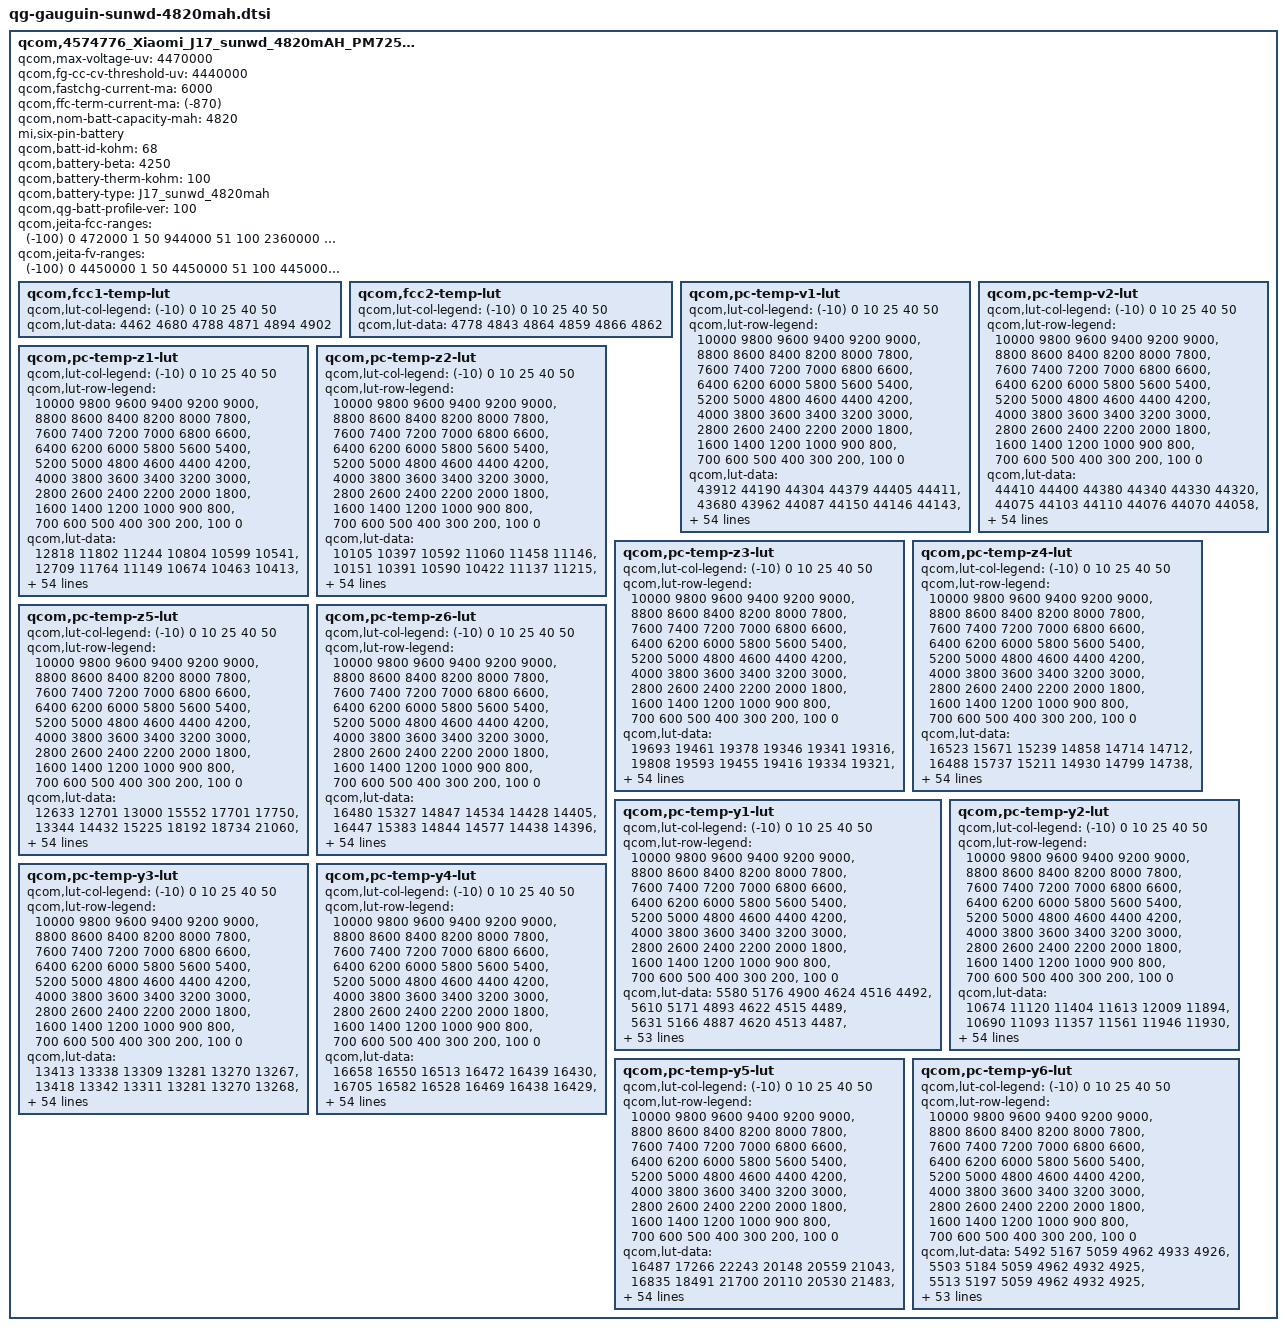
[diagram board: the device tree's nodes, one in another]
qcom,4574776_Xiaomi_J17_sunwd_4820mAH_PM7250B {
    /* 4574776_Xiaomi_J17_sunwd_4820mAH_PM7250B_averaged_MasterSlave_May19th2020 */
    qcom,max-voltage-uv = <4470000>;
    qcom,fg-cc-cv-threshold-uv = <4440000>;
    qcom,fastchg-current-ma = <6000>;
    qcom,ffc-term-current-ma = <(-870)>;
    qcom,nom-batt-capacity-mah = <4820>;
    mi,six-pin-battery;
    qcom,batt-id-kohm = <68>;
    qcom,battery-beta = <4250>;
    qcom,battery-therm-kohm = <100>;
    qcom,battery-type = "J17_sunwd_4820mah";
    qcom,qg-batt-profile-ver = <100>;
   	qcom,jeita-fcc-ranges = <(-100)	0	472000
			1  50  944000
			51  100	2360000
			101 150	3776000
			151 480	6000000
			481 600	2360000>;
	qcom,jeita-fv-ranges = <(-100)  0   4450000
			1   50  4450000
			51  100	4450000
			101 150	4450000
			151 480	4480000
			481 600	4200000>;

	qcom,fcc1-temp-lut {
		qcom,lut-col-legend = <(-10) 0 10 25 40 50>;
		qcom,lut-data = <4462 4680 4788 4871 4894 4902>;
	};

	qcom,fcc2-temp-lut {
		qcom,lut-col-legend = <(-10) 0 10 25 40 50>;
		qcom,lut-data = <4778 4843 4864 4859 4866 4862>;
	};

	qcom,pc-temp-v1-lut {
		qcom,lut-col-legend = <(-10) 0 10 25 40 50>;
		qcom,lut-row-legend = <10000 9800 9600 9400 9200 9000>,
			<8800 8600 8400 8200 8000 7800>,
			<7600 7400 7200 7000 6800 6600>,
			<6400 6200 6000 5800 5600 5400>,
			<5200 5000 4800 4600 4400 4200>,
			<4000 3800 3600 3400 3200 3000>,
			<2800 2600 2400 2200 2000 1800>,
			<1600 1400 1200 1000 900 800>,
			<700 600 500 400 300 200>,
			<100 0>;
		qcom,lut-data = <43912 44190 44304 44379 44405 44411>,
			<43680 43962 44087 44150 44146 44143>,
			<43449 43743 43869 43937 43929 43924>,
			<43218 43528 43654 43725 43720 43719>,
			<42987 43304 43439 43507 43504 43505>,
			<42751 43068 43214 43284 43285 43290>,
			<42514 42827 42973 43049 43058 43065>,
			<42281 42588 42727 42803 42819 42826>,
			<42053 42347 42481 42555 42575 42581>,
			<41829 42109 42234 42308 42328 42336>,
			<41611 41876 41992 42062 42079 42089>,
			<41396 41647 41755 41820 41836 41847>,
			<41189 41424 41524 41579 41595 41609>,
			<40996 41207 41298 41345 41360 41375>,
			<40810 40994 41077 41120 41132 41146>,
			<40622 40785 40864 40902 40911 40922>,
			<40420 40582 40657 40692 40698 40706>,
			<40220 40387 40458 40488 40491 40498>,
			<40044 40198 40276 40295 40295 40300>,
			<39891 40018 40107 40122 40116 40118>,
			<39744 39854 39922 39946 39943 39943>,
			<39587 39698 39695 39722 39735 39740>,
			<39428 39504 39462 39454 39487 39501>,
			<39268 39215 39249 39232 39262 39278>,
			<39096 38953 39046 39065 39076 39089>,
			<38928 38824 38889 38922 38913 38921>,
			<38808 38739 38781 38793 38779 38781>,
			<38723 38666 38690 38677 38667 38664>,
			<38654 38597 38597 38575 38564 38557>,
			<38593 38535 38505 38482 38466 38457>,
			<38541 38474 38423 38400 38376 38366>,
			<38493 38413 38350 38326 38294 38281>,
			<38446 38358 38285 38260 38220 38203>,
			<38400 38306 38230 38202 38155 38132>,
			<38358 38259 38183 38153 38099 38071>,
			<38320 38219 38141 38106 38046 38011>,
			<38281 38186 38106 38058 37987 37941>,
			<38237 38148 38070 38009 37926 37862>,
			<38188 38086 38014 37944 37853 37780>,
			<38130 38001 37924 37857 37767 37695>,
			<38053 37902 37820 37754 37668 37600>,
			<37951 37783 37702 37638 37555 37482>,
			<37817 37642 37563 37502 37422 37343>,
			<37646 37468 37395 37335 37256 37181>,
			<37458 37305 37230 37176 37106 37037>,
			<37313 37189 37129 37073 37017 36953>,
			<37259 37157 37094 37047 36993 36932>,
			<37213 37128 37071 37030 36976 36920>,
			<37176 37111 37056 37011 36959 36903>,
			<37144 37070 37016 36968 36911 36839>,
			<37102 36934 36807 36716 36624 36537>,
			<36971 36511 36353 36266 36178 36082>,
			<36571 35941 35752 35670 35583 35487>,
			<36008 35149 34896 34852 34771 34672>,
			<35112 33752 33465 33560 33492 33393>,
			<30000 30000 30000 30000 30000 30000>;
	};

	qcom,pc-temp-v2-lut {
		qcom,lut-col-legend = <(-10) 0 10 25 40 50>;
		qcom,lut-row-legend = <10000 9800 9600 9400 9200 9000>,
			<8800 8600 8400 8200 8000 7800>,
			<7600 7400 7200 7000 6800 6600>,
			<6400 6200 6000 5800 5600 5400>,
			<5200 5000 4800 4600 4400 4200>,
			<4000 3800 3600 3400 3200 3000>,
			<2800 2600 2400 2200 2000 1800>,
			<1600 1400 1200 1000 900 800>,
			<700 600 500 400 300 200>,
			<100 0>;
		qcom,lut-data = <44410 44400 44380 44340 44330 44320>,
			<44075 44103 44110 44076 44070 44058>,
			<43773 43831 43856 43825 43823 43809>,
			<43511 43591 43623 43593 43592 43578>,
			<43288 43381 43411 43379 43378 43364>,
			<43067 43165 43194 43159 43159 43145>,
			<42834 42925 42957 42922 42924 42911>,
			<42596 42677 42712 42679 42683 42671>,
			<42357 42429 42467 42434 42440 42429>,
			<42113 42181 42219 42187 42193 42183>,
			<41876 41936 41973 41942 41949 41940>,
			<41660 41697 41731 41700 41708 41700>,
			<41451 41464 41493 41462 41470 41463>,
			<41230 41240 41260 41231 41238 41232>,
			<40996 41024 41032 41005 41011 41005>,
			<40747 40811 40810 40786 40791 40786>,
			<40471 40603 40599 40573 40579 40574>,
			<40179 40391 40392 40366 40375 40369>,
			<39919 40146 40187 40174 40184 40177>,
			<39690 39866 39984 39994 40002 39997>,
			<39477 39604 39764 39792 39804 39801>,
			<39272 39372 39501 39541 39572 39570>,
			<39079 39160 39243 39286 39336 39335>,
			<38899 38976 39037 39076 39123 39126>,
			<38733 38812 38861 38889 38922 38930>,
			<38575 38663 38708 38733 38759 38769>,
			<38418 38527 38575 38603 38632 38642>,
			<38267 38403 38457 38490 38521 38531>,
			<38157 38286 38347 38384 38415 38425>,
			<38081 38177 38245 38285 38317 38326>,
			<38019 38080 38153 38196 38228 38236>,
			<37960 37991 38067 38114 38149 38154>,
			<37908 37916 37989 38039 38075 38078>,
			<37855 37865 37915 37970 38007 38008>,
			<37801 37829 37845 37907 37944 37941>,
			<37746 37792 37790 37839 37864 37855>,
			<37689 37757 37750 37768 37759 37730>,
			<37632 37719 37709 37691 37649 37600>,
			<37565 37669 37651 37607 37553 37499>,
			<37486 37604 37578 37518 37461 37407>,
			<37396 37522 37487 37422 37365 37310>,
			<37293 37405 37361 37319 37265 37209>,
			<37176 37257 37224 37201 37149 37092>,
			<37067 37059 37073 37064 37015 36955>,
			<36960 36885 36907 36913 36872 36822>,
			<36857 36793 36841 36873 36846 36798>,
			<36812 36759 36811 36854 36834 36785>,
			<36767 36725 36783 36839 36817 36767>,
			<36716 36684 36738 36804 36788 36736>,
			<36670 36618 36646 36720 36690 36606>,
			<36596 36423 36355 36426 36347 36247>,
			<36448 35985 35818 35930 35841 35726>,
			<36075 35308 35101 35268 35174 35049>,
			<35423 34244 34089 34369 34243 34096>,
			<34457 32755 32350 32876 32827 32696>,
			<32941 29856 27432 27497 27882 27883>;
	};

	qcom,pc-temp-z1-lut {
		qcom,lut-col-legend = <(-10) 0 10 25 40 50>;
		qcom,lut-row-legend = <10000 9800 9600 9400 9200 9000>,
			<8800 8600 8400 8200 8000 7800>,
			<7600 7400 7200 7000 6800 6600>,
			<6400 6200 6000 5800 5600 5400>,
			<5200 5000 4800 4600 4400 4200>,
			<4000 3800 3600 3400 3200 3000>,
			<2800 2600 2400 2200 2000 1800>,
			<1600 1400 1200 1000 900 800>,
			<700 600 500 400 300 200>,
			<100 0>;
		qcom,lut-data = <12818 11802 11244 10804 10599 10541>,
			<12709 11764 11149 10674 10463 10413>,
			<12658 11708 11083 10635 10438 10392>,
			<12627 11642 11052 10612 10425 10381>,
			<12613 11597 11033 10593 10416 10375>,
			<12613 11570 11014 10580 10410 10372>,
			<12613 11547 10992 10571 10407 10370>,
			<12613 11522 10973 10565 10405 10369>,
			<12611 11496 10957 10560 10404 10368>,
			<12608 11480 10944 10556 10402 10367>,
			<12601 11473 10940 10552 10400 10367>,
			<12586 11468 10940 10549 10399 10367>,
			<12575 11460 10941 10547 10398 10367>,
			<12583 11447 10940 10545 10397 10367>,
			<12605 11439 10938 10545 10397 10367>,
			<12615 11437 10935 10545 10398 10368>,
			<12606 11436 10931 10545 10398 10368>,
			<12592 11435 10928 10546 10398 10368>,
			<12592 11435 10929 10547 10399 10369>,
			<12616 11435 10933 10549 10400 10370>,
			<12639 11437 10936 10551 10401 10371>,
			<12638 11443 10938 10553 10402 10372>,
			<12629 11449 10939 10555 10404 10374>,
			<12624 11455 10942 10558 10406 10376>,
			<12639 11459 10949 10562 10408 10378>,
			<12667 11458 10953 10566 10411 10379>,
			<12687 11454 10954 10569 10413 10381>,
			<12704 11452 10954 10573 10415 10382>,
			<12714 11456 10959 10577 10416 10383>,
			<12709 11463 10971 10579 10419 10385>,
			<12683 11469 10978 10582 10421 10387>,
			<12665 11473 10975 10585 10423 10389>,
			<12666 11477 10972 10588 10425 10391>,
			<12668 11480 10973 10592 10427 10393>,
			<12672 11483 10980 10597 10429 10394>,
			<12689 11488 10989 10602 10432 10395>,
			<12708 11496 10997 10606 10434 10397>,
			<12711 11507 11004 10611 10437 10399>,
			<12706 11517 11009 10615 10440 10400>,
			<12702 11529 11013 10620 10442 10401>,
			<12721 11544 11017 10625 10444 10402>,
			<12759 11568 11027 10630 10445 10404>,
			<12762 11587 11041 10635 10446 10405>,
			<12758 11601 11062 10639 10448 10406>,
			<12780 11598 11067 10646 10452 10407>,
			<12782 11640 11062 10649 10453 10408>,
			<12723 11631 11064 10657 10456 10408>,
			<12718 11631 11078 10653 10452 10408>,
			<12746 11617 11067 10654 10453 10409>,
			<12768 11608 11086 10660 10456 10410>,
			<12774 11668 11086 10663 10460 10412>,
			<12794 11655 11112 10672 10464 10416>,
			<12837 11706 11121 10684 10469 10421>,
			<12934 11736 11137 10696 10477 10427>,
			<12934 11736 11137 10696 10477 10427>,
			<12934 11736 11137 10696 10477 10427>;
	};

	qcom,pc-temp-z2-lut {
		qcom,lut-col-legend = <(-10) 0 10 25 40 50>;
		qcom,lut-row-legend = <10000 9800 9600 9400 9200 9000>,
			<8800 8600 8400 8200 8000 7800>,
			<7600 7400 7200 7000 6800 6600>,
			<6400 6200 6000 5800 5600 5400>,
			<5200 5000 4800 4600 4400 4200>,
			<4000 3800 3600 3400 3200 3000>,
			<2800 2600 2400 2200 2000 1800>,
			<1600 1400 1200 1000 900 800>,
			<700 600 500 400 300 200>,
			<100 0>;
		qcom,lut-data = <10105 10397 10592 11060 11458 11146>,
			<10151 10391 10590 10422 11137 11215>,
			<10173 10380 10586 10676 11129 11202>,
			<10186 10361 10567 10857 11113 11175>,
			<10191 10339 10524 10822 11082 11124>,
			<10191 10304 10485 10762 11027 11035>,
			<10191 10271 10446 10746 10982 11000>,
			<10191 10253 10420 10744 10944 11013>,
			<10198 10240 10426 10743 10922 11035>,
			<10208 10236 10448 10751 10935 11071>,
			<10216 10238 10469 10768 10966 11121>,
			<10224 10245 10490 10781 10975 11135>,
			<10233 10260 10509 10793 10975 11111>,
			<10243 10299 10525 10805 10975 11090>,
			<10255 10334 10539 10816 10981 11109>,
			<10261 10352 10553 10826 10996 11158>,
			<10261 10366 10566 10831 11016 11195>,
			<10262 10387 10580 10834 11049 11222>,
			<10263 10419 10594 10839 11072 11244>,
			<10272 10439 10607 10853 11078 11261>,
			<10281 10440 10624 10872 11082 11276>,
			<10279 10439 10659 10888 11094 11294>,
			<10272 10439 10689 10903 11123 11316>,
			<10262 10449 10677 10921 11139 11326>,
			<10248 10464 10627 10953 11132 11208>,
			<10232 10478 10604 10978 11113 11026>,
			<10229 10491 10615 10952 11060 10983>,
			<10242 10501 10630 10869 10929 10971>,
			<10257 10508 10634 10829 10868 10968>,
			<10262 10513 10635 10820 10879 10996>,
			<10263 10516 10637 10816 10901 11046>,
			<10265 10518 10642 10830 10928 11090>,
			<10269 10520 10650 10872 10965 11134>,
			<10275 10526 10665 10906 11010 11187>,
			<10284 10534 10690 10928 11064 11260>,
			<10300 10539 10708 10950 11129 11337>,
			<10320 10541 10714 10983 11214 11402>,
			<10338 10544 10719 11022 11316 11461>,
			<10355 10553 10728 11050 11381 11489>,
			<10366 10565 10745 11071 11425 11498>,
			<10356 10569 10753 11081 11448 11506>,
			<10324 10563 10747 11072 11398 11540>,
			<10277 10561 10742 11053 11314 11579>,
			<10200 10577 10745 11030 11302 11453>,
			<10084 10789 10840 11049 11321 11397>,
			<10060 10842 10910 11091 11354 11424>,
			<10032 10873 10922 11085 11336 11438>,
			<9978 10898 10916 11052 11355 11505>,
			<9802 11178 11309 11021 11300 11606>,
			<9716 11193 11279 11090 11451 11561>,
			<9699 11138 11471 11114 11122 11202>,
			<9623 10896 11478 11060 11132 11124>,
			<9518 10630 11477 10988 11056 11074>,
			<9294 10426 10747 10885 10979 11031>,
			<9294 10426 10747 10885 10979 11031>,
			<9294 10426 10747 10885 10979 11031>;
	};

	qcom,pc-temp-z3-lut {
		qcom,lut-col-legend = <(-10) 0 10 25 40 50>;
		qcom,lut-row-legend = <10000 9800 9600 9400 9200 9000>,
			<8800 8600 8400 8200 8000 7800>,
			<7600 7400 7200 7000 6800 6600>,
			<6400 6200 6000 5800 5600 5400>,
			<5200 5000 4800 4600 4400 4200>,
			<4000 3800 3600 3400 3200 3000>,
			<2800 2600 2400 2200 2000 1800>,
			<1600 1400 1200 1000 900 800>,
			<700 600 500 400 300 200>,
			<100 0>;
		qcom,lut-data = <19693 19461 19378 19346 19341 19316>,
			<19808 19593 19455 19416 19334 19321>,
			<19856 19644 19503 19409 19344 19325>,
			<19884 19676 19514 19405 19350 19327>,
			<19896 19690 19519 19407 19353 19327>,
			<19888 19698 19523 19411 19354 19325>,
			<19867 19702 19525 19412 19354 19324>,
			<19850 19700 19527 19408 19345 19322>,
			<19837 19692 19524 19404 19337 19321>,
			<19824 19684 19515 19395 19336 19321>,
			<19811 19678 19506 19386 19335 19321>,
			<19798 19672 19498 19383 19334 19320>,
			<19784 19662 19491 19382 19332 19314>,
			<19768 19643 19486 19380 19330 19309>,
			<19751 19632 19482 19376 19326 19308>,
			<19744 19633 19479 19370 19321 19308>,
			<19751 19635 19475 19366 19319 19308>,
			<19762 19633 19471 19363 19318 19307>,
			<19763 19609 19468 19362 19318 19305>,
			<19750 19590 19465 19363 19317 19304>,
			<19738 19594 19464 19364 19316 19303>,
			<19746 19605 19475 19368 19316 19303>,
			<19774 19614 19488 19376 19318 19306>,
			<19792 19622 19486 19379 19320 19310>,
			<19795 19627 19472 19378 19335 19319>,
			<19796 19624 19465 19375 19352 19328>,
			<19797 19613 19467 19381 19352 19329>,
			<19798 19605 19470 19398 19345 19328>,
			<19798 19603 19476 19404 19339 19326>,
			<19797 19601 19486 19400 19336 19321>,
			<19789 19601 19490 19394 19333 19315>,
			<19780 19602 19488 19389 19331 19311>,
			<19773 19602 19485 19384 19328 19309>,
			<19767 19602 19481 19380 19326 19308>,
			<19761 19600 19476 19375 19324 19307>,
			<19758 19598 19473 19373 19323 19306>,
			<19755 19595 19471 19372 19323 19306>,
			<19750 19591 19469 19372 19323 19305>,
			<19737 19586 19466 19372 19323 19305>,
			<19715 19580 19460 19369 19324 19307>,
			<19560 19574 19455 19366 19325 19309>,
			<19292 19566 19452 19363 19322 19310>,
			<19260 19557 19448 19361 19319 19311>,
			<19260 19546 19442 19358 19320 19310>,
			<19260 19492 19427 19352 19318 19308>,
			<19260 19473 19401 19346 19311 19303>,
			<19261 19455 19405 19345 19310 19301>,
			<19261 19438 19400 19340 19309 19295>,
			<19262 19304 19326 19339 19307 19292>,
			<19263 19300 19337 19337 19303 19296>,
			<19263 19295 19312 19341 19322 19306>,
			<19264 19297 19313 19346 19316 19306>,
			<19266 19297 19303 19350 19320 19309>,
			<19276 19323 19412 19355 19320 19309>,
			<19276 19323 19412 19355 19320 19309>,
			<19276 19323 19412 19355 19320 19309>;
	};

	qcom,pc-temp-z4-lut {
		qcom,lut-col-legend = <(-10) 0 10 25 40 50>;
		qcom,lut-row-legend = <10000 9800 9600 9400 9200 9000>,
			<8800 8600 8400 8200 8000 7800>,
			<7600 7400 7200 7000 6800 6600>,
			<6400 6200 6000 5800 5600 5400>,
			<5200 5000 4800 4600 4400 4200>,
			<4000 3800 3600 3400 3200 3000>,
			<2800 2600 2400 2200 2000 1800>,
			<1600 1400 1200 1000 900 800>,
			<700 600 500 400 300 200>,
			<100 0>;
		qcom,lut-data = <16523 15671 15239 14858 14714 14712>,
			<16488 15737 15211 14930 14799 14738>,
			<16361 15654 15166 14897 14778 14729>,
			<16049 15444 15096 14856 14749 14714>,
			<15778 15282 14998 14818 14725 14700>,
			<15664 15170 14923 14780 14703 14685>,
			<15584 15080 14872 14750 14692 14676>,
			<15515 15013 14832 14725 14689 14671>,
			<15449 14959 14798 14711 14685 14667>,
			<15394 14915 14770 14708 14679 14661>,
			<15356 14877 14755 14706 14672 14655>,
			<15326 14845 14749 14702 14667 14652>,
			<15304 14822 14745 14693 14662 14651>,
			<15288 14805 14740 14688 14659 14651>,
			<15275 14792 14735 14685 14656 14648>,
			<15271 14781 14733 14684 14654 14641>,
			<15290 14772 14733 14682 14652 14636>,
			<15317 14773 14733 14680 14647 14632>,
			<15316 14791 14729 14677 14643 14629>,
			<15255 14806 14717 14672 14640 14626>,
			<15197 14790 14712 14667 14638 14625>,
			<15202 14756 14725 14683 14647 14630>,
			<15240 14750 14750 14737 14691 14663>,
			<15296 14823 14783 14762 14717 14684>,
			<15425 14897 14827 14763 14705 14680>,
			<15589 14901 14846 14763 14688 14671>,
			<15636 14895 14830 14753 14680 14664>,
			<15593 14886 14804 14721 14676 14657>,
			<15529 14872 14782 14705 14672 14652>,
			<15471 14855 14762 14700 14667 14650>,
			<15406 14840 14751 14698 14662 14648>,
			<15358 14827 14749 14698 14659 14645>,
			<15337 14816 14748 14698 14656 14641>,
			<15322 14809 14748 14698 14655 14639>,
			<15307 14803 14748 14698 14656 14638>,
			<15294 14797 14749 14697 14656 14638>,
			<15279 14791 14746 14699 14660 14643>,
			<15254 14785 14743 14704 14670 14657>,
			<15205 14778 14740 14705 14673 14661>,
			<15170 14770 14738 14705 14671 14656>,
			<15258 14760 14734 14704 14668 14649>,
			<15437 14743 14721 14697 14663 14643>,
			<15448 14726 14703 14684 14657 14639>,
			<15411 14708 14689 14676 14653 14638>,
			<15358 14680 14665 14662 14647 14635>,
			<15348 14675 14658 14646 14639 14628>,
			<15335 14685 14647 14639 14632 14623>,
			<15325 14700 14644 14632 14623 14619>,
			<15313 14844 14720 14624 14616 14613>,
			<15298 14843 14703 14625 14621 14612>,
			<15275 14846 14737 14632 14614 14612>,
			<15262 14852 14740 14626 14618 14611>,
			<15287 14856 14751 14622 14615 14609>,
			<15337 14844 14644 14617 14614 14609>,
			<15337 14844 14644 14617 14614 14609>,
			<15337 14844 14644 14617 14614 14609>;
	};

	qcom,pc-temp-z5-lut {
		qcom,lut-col-legend = <(-10) 0 10 25 40 50>;
		qcom,lut-row-legend = <10000 9800 9600 9400 9200 9000>,
			<8800 8600 8400 8200 8000 7800>,
			<7600 7400 7200 7000 6800 6600>,
			<6400 6200 6000 5800 5600 5400>,
			<5200 5000 4800 4600 4400 4200>,
			<4000 3800 3600 3400 3200 3000>,
			<2800 2600 2400 2200 2000 1800>,
			<1600 1400 1200 1000 900 800>,
			<700 600 500 400 300 200>,
			<100 0>;
		qcom,lut-data = <12633 12701 13000 15552 17701 17750>,
			<13344 14432 15225 18192 18734 21060>,
			<13968 15369 16802 18669 20121 21603>,
			<14563 16028 17535 19038 21256 21851>,
			<14969 16708 17987 19627 22206 22089>,
			<15142 17432 18574 20284 23015 22276>,
			<15254 18148 19404 21173 23155 22496>,
			<15387 18825 20362 22489 22010 22756>,
			<15596 19472 21577 23184 20963 23099>,
			<15777 20254 22973 22486 21271 23849>,
			<15815 21374 23477 21448 22099 24985>,
			<15821 22625 23499 21487 22598 25203>,
			<15824 23640 23519 22468 22898 23306>,
			<15764 24449 23698 23029 23045 21599>,
			<15613 25519 24214 22572 22541 21967>,
			<15540 28226 24757 21960 21601 23092>,
			<15612 31481 25413 21935 21499 24131>,
			<15755 31664 25909 22263 22360 25069>,
			<15900 27188 25892 22817 23443 26106>,
			<16047 23531 25714 24764 24698 27672>,
			<16267 25617 25890 27255 25857 29255>,
			<17049 31466 34370 28740 25383 28690>,
			<18776 37463 44197 29896 22202 23571>,
			<19758 44926 42140 30102 20352 20236>,
			<19573 50339 31580 25368 21524 20664>,
			<19168 47995 25719 20163 23110 21596>,
			<18749 39836 24802 21252 23273 22774>,
			<18199 34698 24336 26020 23072 24501>,
			<17766 32914 25403 29464 22991 25306>,
			<17720 31883 29832 31294 23918 25113>,
			<17747 32050 33833 32704 25516 24869>,
			<17791 33424 36788 33894 26997 25238>,
			<17906 35002 38934 34890 28626 26945>,
			<18123 36616 39379 35687 30453 29057>,
			<18359 38143 39526 36396 33091 32396>,
			<18687 38709 39571 36883 35023 35088>,
			<18970 38877 39357 37103 34287 33573>,
			<18999 39052 38889 37246 31992 28967>,
			<18846 39542 38109 36952 30764 27321>,
			<18548 40210 36638 33848 30425 28342>,
			<16138 40275 35703 31149 30071 29936>,
			<11802 38540 35534 30912 28892 32058>,
			<11176 37730 35357 30760 27621 33968>,
			<11133 38744 34619 29301 27911 31097>,
			<11148 37528 36662 29337 27156 28674>,
			<11081 32970 29344 31799 25482 27455>,
			<11042 25020 32683 33524 27777 28746>,
			<11028 23416 30670 31867 32844 28143>,
			<11014 12317 14228 33921 37628 31334>,
			<10974 12242 15078 31657 27245 32593>,
			<10947 12172 13532 26048 42877 37437>,
			<10948 12147 13335 28691 29617 36163>,
			<10913 12051 13050 31740 35241 41257>,
			<10887 12884 34500 38915 34257 40513>,
			<10887 12884 34500 38915 34257 40513>,
			<10887 12884 34500 38915 34257 40513>;
	};

	qcom,pc-temp-z6-lut {
		qcom,lut-col-legend = <(-10) 0 10 25 40 50>;
		qcom,lut-row-legend = <10000 9800 9600 9400 9200 9000>,
			<8800 8600 8400 8200 8000 7800>,
			<7600 7400 7200 7000 6800 6600>,
			<6400 6200 6000 5800 5600 5400>,
			<5200 5000 4800 4600 4400 4200>,
			<4000 3800 3600 3400 3200 3000>,
			<2800 2600 2400 2200 2000 1800>,
			<1600 1400 1200 1000 900 800>,
			<700 600 500 400 300 200>,
			<100 0>;
		qcom,lut-data = <16480 15327 14847 14534 14428 14405>,
			<16447 15383 14844 14577 14438 14396>,
			<16362 15346 14835 14554 14430 14392>,
			<16189 15248 14810 14528 14419 14384>,
			<16038 15167 14758 14510 14409 14377>,
			<15964 15106 14717 14494 14401 14369>,
			<15909 15053 14690 14480 14393 14364>,
			<15862 15009 14666 14466 14387 14361>,
			<15817 14970 14644 14456 14381 14359>,
			<15778 14937 14624 14449 14377 14357>,
			<15748 14909 14611 14443 14374 14354>,
			<15723 14886 14603 14438 14371 14351>,
			<15703 14865 14596 14434 14368 14348>,
			<15686 14845 14591 14430 14364 14345>,
			<15672 14833 14586 14426 14361 14342>,
			<15667 14828 14582 14422 14358 14340>,
			<15680 14824 14579 14420 14355 14338>,
			<15699 14821 14577 14417 14353 14335>,
			<15700 14817 14573 14416 14351 14333>,
			<15675 14814 14567 14414 14350 14332>,
			<15652 14809 14564 14414 14348 14331>,
			<15659 14803 14577 14422 14352 14333>,
			<15693 14804 14595 14450 14372 14349>,
			<15738 14841 14609 14463 14386 14361>,
			<15808 14878 14623 14464 14389 14364>,
			<15886 14879 14628 14464 14391 14366>,
			<15908 14873 14622 14463 14390 14365>,
			<15897 14866 14615 14459 14384 14362>,
			<15878 14860 14611 14456 14379 14358>,
			<15856 14854 14608 14452 14375 14354>,
			<15825 14850 14607 14449 14372 14350>,
			<15804 14846 14605 14446 14369 14347>,
			<15800 14844 14604 14444 14366 14344>,
			<15797 14842 14603 14443 14365 14343>,
			<15795 14841 14602 14441 14364 14342>,
			<15794 14840 14602 14440 14364 14341>,
			<15793 14839 14602 14441 14366 14343>,
			<15789 14838 14602 14444 14370 14349>,
			<15780 14838 14601 14445 14372 14351>,
			<15766 14837 14601 14444 14371 14350>,
			<15738 14837 14599 14443 14371 14348>,
			<15702 14834 14595 14440 14368 14346>,
			<15701 14830 14589 14434 14364 14345>,
			<15707 14826 14585 14430 14363 14344>,
			<15707 14799 14573 14423 14360 14342>,
			<15706 14792 14559 14414 14353 14336>,
			<15703 14789 14557 14411 14349 14333>,
			<15709 14788 14554 14406 14345 14328>,
			<15712 14783 14550 14402 14341 14324>,
			<15711 14784 14552 14403 14341 14326>,
			<15714 14792 14558 14409 14349 14332>,
			<15728 14803 14565 14411 14349 14333>,
			<15771 14815 14573 14414 14350 14334>,
			<15836 14839 14593 14418 14352 14336>,
			<15836 14839 14593 14418 14352 14336>,
			<15836 14839 14593 14418 14352 14336>;
	};

	qcom,pc-temp-y1-lut {
		qcom,lut-col-legend = <(-10) 0 10 25 40 50>;
		qcom,lut-row-legend = <10000 9800 9600 9400 9200 9000>,
			<8800 8600 8400 8200 8000 7800>,
			<7600 7400 7200 7000 6800 6600>,
			<6400 6200 6000 5800 5600 5400>,
			<5200 5000 4800 4600 4400 4200>,
			<4000 3800 3600 3400 3200 3000>,
			<2800 2600 2400 2200 2000 1800>,
			<1600 1400 1200 1000 900 800>,
			<700 600 500 400 300 200>,
			<100 0>;
		qcom,lut-data = <5580 5176 4900 4624 4516 4492>,
			<5610 5171 4893 4622 4515 4489>,
			<5631 5166 4887 4620 4513 4487>,
			<5643 5162 4881 4617 4512 4486>,
			<5649 5159 4875 4615 4510 4485>,
			<5651 5158 4871 4612 4509 4485>,
			<5644 5159 4868 4609 4509 4485>,
			<5632 5161 4866 4606 4509 4486>,
			<5631 5160 4864 4603 4508 4486>,
			<5645 5155 4861 4600 4508 4485>,
			<5657 5150 4858 4598 4507 4484>,
			<5658 5149 4855 4598 4506 4485>,
			<5659 5147 4852 4598 4505 4485>,
			<5658 5150 4847 4597 4505 4485>,
			<5648 5161 4842 4595 4505 4486>,
			<5640 5167 4840 4594 4505 4487>,
			<5641 5166 4841 4594 4505 4487>,
			<5644 5165 4843 4594 4505 4487>,
			<5648 5165 4845 4594 4506 4487>,
			<5660 5167 4846 4594 4506 4487>,
			<5669 5170 4846 4595 4507 4487>,
			<5665 5176 4846 4597 4507 4488>,
			<5655 5183 4846 4599 4507 4488>,
			<5652 5189 4847 4600 4507 4489>,
			<5658 5195 4853 4601 4509 4491>,
			<5668 5197 4855 4602 4511 4492>,
			<5687 5191 4856 4604 4512 4492>,
			<5715 5184 4856 4608 4513 4492>,
			<5722 5183 4859 4611 4514 4492>,
			<5689 5184 4864 4614 4515 4493>,
			<5656 5185 4867 4617 4516 4493>,
			<5654 5186 4869 4620 4518 4495>,
			<5654 5188 4870 4623 4519 4497>,
			<5654 5190 4872 4626 4521 4498>,
			<5660 5193 4874 4629 4522 4499>,
			<5667 5195 4877 4631 4524 4500>,
			<5673 5196 4880 4634 4525 4501>,
			<5678 5198 4882 4637 4526 4502>,
			<5679 5197 4885 4640 4527 4503>,
			<5676 5193 4888 4642 4529 4504>,
			<5673 5192 4892 4644 4530 4504>,
			<5677 5200 4897 4645 4530 4504>,
			<5686 5205 4905 4647 4531 4505>,
			<5679 5200 4919 4653 4532 4506>,
			<5667 5203 4923 4660 4536 4508>,
			<5693 5217 4929 4664 4536 4509>,
			<5708 5219 4948 4665 4535 4509>,
			<5714 5229 4938 4667 4536 4509>,
			<5717 5241 4944 4672 4538 4510>,
			<5712 5232 4948 4671 4537 4510>,
			<5748 5246 4959 4675 4538 4510>,
			<5822 5296 4954 4685 4541 4512>,
			<5862 5340 4983 4696 4545 4516>,
			<5853 5151 5064 4711 4549 4521>,
			<5853 5151 5064 4711 4549 4521>,
			<5853 5151 5064 4711 4549 4521>;
	};

	qcom,pc-temp-y2-lut {
		qcom,lut-col-legend = <(-10) 0 10 25 40 50>;
		qcom,lut-row-legend = <10000 9800 9600 9400 9200 9000>,
			<8800 8600 8400 8200 8000 7800>,
			<7600 7400 7200 7000 6800 6600>,
			<6400 6200 6000 5800 5600 5400>,
			<5200 5000 4800 4600 4400 4200>,
			<4000 3800 3600 3400 3200 3000>,
			<2800 2600 2400 2200 2000 1800>,
			<1600 1400 1200 1000 900 800>,
			<700 600 500 400 300 200>,
			<100 0>;
		qcom,lut-data = <10674 11120 11404 11613 12009 11894>,
			<10690 11093 11357 11561 11946 11930>,
			<10720 11066 11312 11511 11881 11946>,
			<10753 11040 11269 11465 11814 11946>,
			<10782 11013 11228 11423 11747 11934>,
			<10795 10987 11188 11388 11678 11912>,
			<10797 10954 11147 11353 11592 11832>,
			<10798 10927 11110 11327 11518 11726>,
			<10801 10923 11083 11327 11501 11687>,
			<10816 10926 11060 11341 11495 11666>,
			<10836 10931 11051 11352 11494 11659>,
			<10860 10957 11052 11359 11515 11671>,
			<10893 10998 11054 11363 11542 11686>,
			<10939 11024 11068 11362 11537 11682>,
			<11023 11040 11120 11355 11504 11661>,
			<11080 11065 11178 11351 11490 11651>,
			<11062 11151 11234 11363 11529 11684>,
			<11024 11244 11292 11391 11586 11722>,
			<11015 11250 11351 11463 11616 11726>,
			<11037 11225 11411 11619 11636 11726>,
			<11056 11210 11431 11687 11672 11728>,
			<11055 11208 11402 11672 11791 11772>,
			<11049 11206 11370 11651 11911 11838>,
			<11040 11211 11375 11638 11941 11882>,
			<11024 11231 11398 11627 11954 11919>,
			<11011 11244 11416 11625 11968 11956>,
			<11011 11248 11426 11656 11988 11991>,
			<11013 11250 11436 11702 12007 12031>,
			<11012 11250 11453 11736 12020 12094>,
			<10993 11248 11474 11767 12029 12178>,
			<10951 11248 11481 11793 12044 12229>,
			<10691 11263 11474 11815 12069 12250>,
			<10082 11282 11466 11834 12101 12271>,
			<9792 11274 11460 11853 12146 12324>,
			<9741 11237 11454 11869 12200 12398>,
			<9713 11199 11448 11873 12208 12422>,
			<9699 11169 11443 11854 12153 12422>,
			<9691 11136 11436 11824 12107 12422>,
			<9684 11091 11414 11784 12112 12405>,
			<9679 11034 11370 11730 12125 12355>,
			<9675 10960 11312 11691 12128 12293>,
			<9672 10870 11219 11662 12122 12195>,
			<9670 10671 11143 11661 12101 12175>,
			<9668 9912 11084 11700 12020 12216>,
			<9666 9725 10929 11574 11939 12171>,
			<9664 9705 10899 11586 11970 12044>,
			<9663 9691 10799 11555 11920 11935>,
			<9662 9680 10709 11585 11889 11791>,
			<9660 9671 10600 11539 11791 11837>,
			<9657 9665 10487 11491 11699 11818>,
			<9653 9659 9968 11467 11795 11817>,
			<9649 9652 9712 11383 11708 11747>,
			<9648 9649 9663 11267 11557 11586>,
			<9648 9649 9653 11142 11539 11502>,
			<9648 9649 9653 11142 11539 11502>,
			<9648 9649 9653 11142 11539 11502>;
	};

	qcom,pc-temp-y3-lut {
		qcom,lut-col-legend = <(-10) 0 10 25 40 50>;
		qcom,lut-row-legend = <10000 9800 9600 9400 9200 9000>,
			<8800 8600 8400 8200 8000 7800>,
			<7600 7400 7200 7000 6800 6600>,
			<6400 6200 6000 5800 5600 5400>,
			<5200 5000 4800 4600 4400 4200>,
			<4000 3800 3600 3400 3200 3000>,
			<2800 2600 2400 2200 2000 1800>,
			<1600 1400 1200 1000 900 800>,
			<700 600 500 400 300 200>,
			<100 0>;
		qcom,lut-data = <13413 13338 13309 13281 13270 13267>,
			<13418 13342 13311 13281 13270 13268>,
			<13424 13348 13312 13282 13271 13268>,
			<13431 13353 13314 13283 13271 13269>,
			<13436 13358 13315 13284 13272 13270>,
			<13440 13361 13316 13284 13273 13270>,
			<13441 13362 13317 13284 13273 13271>,
			<13442 13363 13318 13284 13274 13271>,
			<13441 13364 13319 13284 13275 13272>,
			<13440 13365 13320 13285 13275 13272>,
			<13438 13366 13321 13286 13276 13273>,
			<13445 13364 13322 13286 13276 13273>,
			<13458 13361 13322 13287 13277 13273>,
			<13458 13361 13322 13288 13277 13274>,
			<13433 13361 13321 13291 13276 13274>,
			<13412 13362 13321 13292 13276 13274>,
			<13411 13360 13320 13291 13278 13274>,
			<13410 13356 13319 13290 13280 13274>,
			<13409 13353 13319 13290 13280 13274>,
			<13401 13348 13320 13292 13280 13275>,
			<13393 13344 13321 13292 13281 13275>,
			<13388 13340 13316 13290 13280 13275>,
			<13384 13336 13310 13287 13278 13274>,
			<13379 13334 13307 13284 13276 13272>,
			<13376 13332 13304 13282 13272 13269>,
			<13372 13331 13303 13281 13270 13268>,
			<13362 13329 13303 13281 13271 13268>,
			<13349 13328 13303 13281 13271 13268>,
			<13342 13326 13302 13280 13270 13268>,
			<13340 13325 13302 13280 13270 13269>,
			<13339 13324 13302 13280 13270 13269>,
			<13341 13320 13301 13281 13271 13269>,
			<13349 13317 13300 13281 13272 13269>,
			<13360 13317 13300 13281 13272 13269>,
			<13373 13321 13299 13281 13272 13269>,
			<13391 13324 13299 13281 13272 13269>,
			<13410 13328 13300 13281 13271 13268>,
			<13433 13331 13302 13281 13270 13267>,
			<13460 13334 13304 13280 13270 13267>,
			<13491 13337 13305 13279 13270 13267>,
			<13528 13340 13306 13279 13270 13267>,
			<13571 13343 13306 13279 13270 13268>,
			<13623 13347 13307 13279 13270 13269>,
			<13692 13353 13310 13280 13270 13269>,
			<13780 13374 13312 13281 13270 13268>,
			<13873 13395 13314 13281 13271 13269>,
			<13912 13423 13317 13282 13272 13270>,
			<14017 13469 13324 13286 13273 13270>,
			<14165 13546 13333 13287 13276 13273>,
			<14430 13690 13347 13291 13276 13271>,
			<15082 13999 13365 13290 13274 13272>,
			<17747 15467 13435 13292 13275 13271>,
			<25369 22126 13789 13296 13276 13272>,
			<59070 55991 16962 13306 13277 13273>,
			<59070 55991 16962 13306 13277 13273>,
			<59070 55991 16962 13306 13277 13273>;
	};

	qcom,pc-temp-y4-lut {
		qcom,lut-col-legend = <(-10) 0 10 25 40 50>;
		qcom,lut-row-legend = <10000 9800 9600 9400 9200 9000>,
			<8800 8600 8400 8200 8000 7800>,
			<7600 7400 7200 7000 6800 6600>,
			<6400 6200 6000 5800 5600 5400>,
			<5200 5000 4800 4600 4400 4200>,
			<4000 3800 3600 3400 3200 3000>,
			<2800 2600 2400 2200 2000 1800>,
			<1600 1400 1200 1000 900 800>,
			<700 600 500 400 300 200>,
			<100 0>;
		qcom,lut-data = <16658 16550 16513 16472 16439 16430>,
			<16705 16582 16528 16469 16438 16429>,
			<16767 16620 16540 16466 16436 16427>,
			<16832 16656 16549 16464 16434 16425>,
			<16887 16683 16555 16463 16433 16423>,
			<16918 16693 16557 16463 16432 16423>,
			<16928 16687 16553 16464 16432 16423>,
			<16934 16677 16547 16465 16432 16423>,
			<16941 16676 16547 16466 16432 16423>,
			<16948 16678 16547 16466 16433 16423>,
			<16953 16682 16547 16467 16434 16423>,
			<16953 16694 16550 16470 16436 16425>,
			<16953 16716 16559 16474 16438 16426>,
			<16959 16737 16569 16477 16441 16428>,
			<17006 16760 16586 16481 16447 16431>,
			<17043 16784 16607 16486 16452 16435>,
			<16999 16813 16645 16499 16456 16439>,
			<16895 16836 16678 16517 16460 16445>,
			<16830 16821 16681 16541 16471 16453>,
			<16796 16743 16681 16573 16491 16465>,
			<16767 16675 16678 16585 16499 16470>,
			<16740 16638 16626 16558 16495 16468>,
			<16715 16609 16559 16518 16488 16464>,
			<16689 16590 16531 16491 16473 16455>,
			<16660 16577 16512 16467 16447 16437>,
			<16634 16566 16503 16459 16438 16430>,
			<16613 16557 16500 16458 16438 16430>,
			<16595 16549 16498 16458 16438 16431>,
			<16590 16538 16498 16460 16440 16432>,
			<16596 16524 16498 16464 16444 16434>,
			<16608 16515 16498 16468 16449 16437>,
			<16625 16509 16499 16473 16453 16442>,
			<16651 16505 16499 16478 16458 16447>,
			<16670 16507 16495 16484 16466 16453>,
			<16681 16521 16486 16489 16474 16460>,
			<16689 16537 16484 16490 16475 16461>,
			<16700 16559 16493 16482 16460 16448>,
			<16710 16584 16503 16469 16444 16435>,
			<16714 16604 16510 16458 16438 16432>,
			<16714 16624 16516 16447 16434 16430>,
			<16712 16630 16520 16445 16432 16429>,
			<16704 16618 16523 16449 16432 16427>,
			<16685 16611 16528 16454 16432 16426>,
			<16682 16610 16539 16461 16434 16426>,
			<16683 16604 16536 16455 16425 16420>,
			<16703 16597 16524 16454 16429 16424>,
			<16694 16606 16537 16462 16434 16426>,
			<16703 16623 16558 16470 16437 16431>,
			<16728 16650 16586 16481 16445 16445>,
			<16748 16686 16628 16498 16452 16439>,
			<16801 16709 16654 16489 16430 16427>,
			<17146 16839 16693 16497 16436 16429>,
			<18423 18598 16805 16523 16452 16444>,
			<27003 47650 18053 16587 16485 16480>,
			<27003 47650 18053 16587 16485 16480>,
			<27003 47650 18053 16587 16485 16480>;
	};

	qcom,pc-temp-y5-lut {
		qcom,lut-col-legend = <(-10) 0 10 25 40 50>;
		qcom,lut-row-legend = <10000 9800 9600 9400 9200 9000>,
			<8800 8600 8400 8200 8000 7800>,
			<7600 7400 7200 7000 6800 6600>,
			<6400 6200 6000 5800 5600 5400>,
			<5200 5000 4800 4600 4400 4200>,
			<4000 3800 3600 3400 3200 3000>,
			<2800 2600 2400 2200 2000 1800>,
			<1600 1400 1200 1000 900 800>,
			<700 600 500 400 300 200>,
			<100 0>;
		qcom,lut-data = <16487 17266 22243 20148 20559 21043>,
			<16835 18491 21700 20110 20530 21483>,
			<17254 19231 21180 19919 20517 22413>,
			<17676 19610 20683 19599 20517 23492>,
			<18029 19749 20213 19175 20527 24376>,
			<18244 19766 19772 18671 20546 24724>,
			<18348 19488 19367 17903 20627 24714>,
			<18414 18949 18980 17162 20725 24690>,
			<18405 18490 18584 16960 20679 24632>,
			<18267 18057 18187 16905 20370 24457>,
			<18163 17591 17746 16820 19981 24189>,
			<19369 16928 17204 16458 19548 23632>,
			<21613 16348 16629 16061 19005 22813>,
			<21977 16306 16068 16124 18198 21905>,
			<20164 16540 15484 16554 17048 20808>,
			<18696 16938 15260 16756 16575 19693>,
			<20176 18402 15372 15863 16961 18400>,
			<23246 20404 15639 14777 17411 17355>,
			<24069 21583 17008 14799 17256 17055>,
			<23265 22476 20688 15450 16631 16906>,
			<22567 22831 22836 16457 16481 16940>,
			<22652 22846 23517 19266 19593 19168>,
			<22935 22856 23870 21942 22939 21633>,
			<23177 23008 23706 22093 22520 21728>,
			<23406 23536 23172 21833 20654 21410>,
			<23551 23931 22979 21650 19939 21278>,
			<21700 24067 23415 21573 20186 21276>,
			<17043 24191 23981 21503 20430 21275>,
			<14892 24560 24273 21377 19863 21058>,
			<14491 25289 24485 21215 18411 20463>,
			<14226 25545 24758 21181 17969 20149>,
			<13914 22692 25213 21592 18794 20038>,
			<13618 19339 25536 22267 19816 19985>,
			<13530 19166 25179 23049 20451 20000>,
			<13704 19833 24322 24064 20974 20060>,
			<13998 20519 24073 25115 21262 20163>,
			<14370 21131 24335 26425 21381 20448>,
			<14862 21732 24562 27284 21537 20900>,
			<15081 22336 24328 26625 22551 21662>,
			<15115 22945 23624 24790 24250 22839>,
			<15131 23150 22675 23308 24590 24035>,
			<14968 22952 21097 22221 23692 25304>,
			<14425 22195 20088 21148 22474 26259>,
			<14071 16638 19592 20146 21172 26975>,
			<13690 14525 19432 23006 27946 30758>,
			<12954 14462 20536 22550 23027 24588>,
			<13181 14498 19335 19961 20477 23747>,
			<13446 14460 18879 21247 20495 23112>,
			<13196 14333 18223 19933 23318 24600>,
			<13724 14507 18043 21598 22845 23087>,
			<13511 14277 16845 22742 27730 35222>,
			<11669 12964 14806 23734 29644 30710>,
			<9861 10003 13906 22780 29247 31402>,
			<9023 8932 10648 22654 27898 28211>,
			<9023 8932 10648 22654 27898 28211>,
			<9023 8932 10648 22654 27898 28211>;
	};

	qcom,pc-temp-y6-lut {
		qcom,lut-col-legend = <(-10) 0 10 25 40 50>;
		qcom,lut-row-legend = <10000 9800 9600 9400 9200 9000>,
			<8800 8600 8400 8200 8000 7800>,
			<7600 7400 7200 7000 6800 6600>,
			<6400 6200 6000 5800 5600 5400>,
			<5200 5000 4800 4600 4400 4200>,
			<4000 3800 3600 3400 3200 3000>,
			<2800 2600 2400 2200 2000 1800>,
			<1600 1400 1200 1000 900 800>,
			<700 600 500 400 300 200>,
			<100 0>;
		qcom,lut-data = <5492 5167 5059 4962 4933 4926>,
			<5503 5184 5059 4962 4932 4925>,
			<5513 5197 5059 4962 4932 4925>,
			<5521 5205 5059 4961 4932 4925>,
			<5527 5210 5059 4961 4932 4925>,
			<5529 5211 5059 4961 4932 4925>,
			<5528 5207 5057 4961 4933 4926>,
			<5524 5201 5054 4961 4933 4926>,
			<5521 5198 5052 4961 4934 4926>,
			<5517 5197 5051 4962 4934 4927>,
			<5515 5196 5051 4963 4935 4928>,
			<5518 5197 5052 4964 4936 4928>,
			<5524 5199 5053 4965 4937 4929>,
			<5525 5203 5055 4967 4938 4930>,
			<5522 5209 5059 4969 4939 4931>,
			<5518 5215 5064 4972 4941 4932>,
			<5504 5220 5073 4975 4943 4933>,
			<5478 5225 5081 4979 4945 4935>,
			<5460 5219 5082 4986 4949 4937>,
			<5448 5194 5083 4996 4955 4941>,
			<5438 5172 5082 5000 4957 4943>,
			<5430 5160 5064 4990 4955 4942>,
			<5425 5150 5041 4977 4952 4940>,
			<5420 5145 5031 4967 4946 4936>,
			<5414 5142 5025 4959 4936 4929>,
			<5410 5140 5022 4956 4932 4926>,
			<5408 5138 5022 4956 4932 4926>,
			<5406 5137 5022 4956 4932 4926>,
			<5406 5136 5022 4957 4933 4927>,
			<5416 5135 5023 4958 4934 4928>,
			<5431 5134 5024 4960 4935 4929>,
			<5447 5135 5025 4962 4937 4930>,
			<5466 5136 5026 4964 4939 4932>,
			<5489 5139 5026 4966 4942 4934>,
			<5515 5151 5025 4968 4945 4936>,
			<5544 5166 5025 4969 4945 4936>,
			<5576 5184 5030 4966 4940 4932>,
			<5613 5206 5036 4963 4935 4928>,
			<5651 5228 5042 4960 4933 4927>,
			<5689 5254 5047 4957 4932 4927>,
			<5731 5279 5054 4956 4932 4927>,
			<5775 5302 5061 4958 4932 4927>,
			<5825 5326 5071 4960 4932 4927>,
			<5888 5352 5086 4964 4933 4927>,
			<5968 5393 5097 4963 4930 4924>,
			<6062 5436 5100 4964 4933 4927>,
			<6102 5486 5116 4967 4934 4928>,
			<6200 5554 5144 4973 4936 4930>,
			<6343 5651 5183 4978 4941 4935>,
			<6593 5804 5239 4986 4942 4933>,
			<7209 6112 5308 4984 4935 4930>,
			<9463 7391 5446 4990 4938 4930>,
			<15320 12825 5882 5004 4943 4936>,
			<37240 44259 8830 5034 4955 4947>,
			<37240 44259 8830 5034 4955 4947>,
			<37240 44259 8830 5034 4955 4947>;
	};

};
